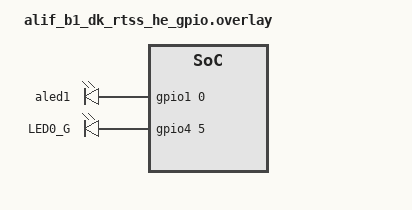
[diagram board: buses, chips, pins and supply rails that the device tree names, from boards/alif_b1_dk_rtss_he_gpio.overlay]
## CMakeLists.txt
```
# Copyright Alif Semiconductor - All Rights Reserved.
# Use, distribution and modification of this code is permitted under the
# terms stated in the Alif Semiconductor Software License Agreement
#
# You should have received a copy of the Alif Semiconductor Software
# License Agreement with this file. If not, please write to:
# contact@alifsemi.com, or visit: https://alifsemi.com/license

cmake_minimum_required(VERSION 3.20.0)
find_package(Zephyr REQUIRED HINTS $ENV{ZEPHYR_BASE})
project(alif_gpio)

target_sources(app PRIVATE
    src/main.c
    src/test_gpio.c
    src/test_gpio_interrupts.c
    src/test_gpio_stress.c
    )
```

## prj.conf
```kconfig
# Copyright Alif Semiconductor - All Rights Reserved.
# Use, distribution and modification of this code is permitted under the
# terms stated in the Alif Semiconductor Software License Agreement
#
# You should have received a copy of the Alif Semiconductor Software
# License Agreement with this file. If not, please write to:
# contact@alifsemi.com, or visit: https://alifsemi.com/license

CONFIG_GPIO=y
CONFIG_ZTEST=y
CONFIG_GPIO_GET_DIRECTION=y
CONFIG_GPIO_ENABLE_DISABLE_INTERRUPT=y
```

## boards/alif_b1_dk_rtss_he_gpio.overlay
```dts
/* Copyright (C) 2025 Alif Semiconductor - All Rights Reserved.
 * Use, distribution and modification of this code is permitted under the
 * terms stated in the Alif Semiconductor Software License Agreement
 *
 * You should have received a copy of the Alif Semiconductor Software
 * License Agreement with this file. If not, please write to:
 * contact@alifsemi.com, or visit: https://alifsemi.com/license
 */

/{
	aliases {
		led1 = &aled1;
		led0 = &aled0;
	};

	leds {
		aled1: led_1 {
			gpios = <&gpio1 0 0>;
		};
		aled0: led_0 {
			gpios = <&gpio4 5 0>;
			label = "LED0_G";
		};
	};
};

&gpio1 {
	status = "okay";
};

&gpio4 {
	status = "okay";
};
```

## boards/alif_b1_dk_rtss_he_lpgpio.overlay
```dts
/* Copyright (C) 2025 Alif Semiconductor - All Rights Reserved.
 * Use, distribution and modification of this code is permitted under the
 * terms stated in the Alif Semiconductor Software License Agreement
 *
 * You should have received a copy of the Alif Semiconductor Software
 * License Agreement with this file. If not, please write to:
 * contact@alifsemi.com, or visit: https://alifsemi.com/license
 */

/{
	aliases {
		led1 = &aled1;
		led0 = &aled0;
	};

	leds {
		aled1: led_1 {
			gpios = <&lpgpio 0 0>;
		};
		aled0: led_0 {
			gpios = <&gpio6 2 0>;
		};
	};
};

&lpgpio {
	status = "okay";
};

&gpio6 {
	status = "okay";
};
```

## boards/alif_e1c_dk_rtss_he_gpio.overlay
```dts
/* Copyright (C) 2025 Alif Semiconductor - All Rights Reserved.
 * Use, distribution and modification of this code is permitted under the
 * terms stated in the Alif Semiconductor Software License Agreement
 *
 * You should have received a copy of the Alif Semiconductor Software
 * License Agreement with this file. If not, please write to:
 * contact@alifsemi.com, or visit: https://alifsemi.com/license
 */

/{
	aliases {
		led1 = &aled1;
		led0 = &aled0;
	};

	leds {
		aled1: led_1 {
			gpios = <&gpio1 0 0>;
		};
		aled0: led_0 {
			gpios = <&gpio4 5 0>;
			label = "LED0_G";
		};
	};
};
```

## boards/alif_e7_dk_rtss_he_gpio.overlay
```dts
/* Copyright (C) 2025 Alif Semiconductor - All Rights Reserved.
 * Use, distribution and modification of this code is permitted under the
 * terms stated in the Alif Semiconductor Software License Agreement
 *
 * You should have received a copy of the Alif Semiconductor Software
 * License Agreement with this file. If not, please write to:
 * contact@alifsemi.com, or visit: https://alifsemi.com/license
 */

/{
	aliases {
		led1 = &aled1;
		led0 = &aled0;
	};

	leds {
		aled1: led_1 {
			gpios = <&gpio1 7 0>;
		};
		aled0: led_0 {
			gpios = <&gpio6 4 0>;
		};
	};
};

&gpio1 {
	status = "okay";
};
```

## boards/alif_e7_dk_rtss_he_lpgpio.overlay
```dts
/* Copyright (C) 2025 Alif Semiconductor - All Rights Reserved.
 * Use, distribution and modification of this code is permitted under the
 * terms stated in the Alif Semiconductor Software License Agreement
 *
 * You should have received a copy of the Alif Semiconductor Software
 * License Agreement with this file. If not, please write to:
 * contact@alifsemi.com, or visit: https://alifsemi.com/license
 */

/{
	aliases {
		led1 = &aled1;
		led0 = &aled0;
	};

	leds {
		aled1: led_1 {
			gpios = <&lpgpio 4 0>;
		};
		aled0: led_0 {
			gpios = <&gpio6 2 0>;
		};
	};
};

&lpgpio {
	status = "okay";
};
```

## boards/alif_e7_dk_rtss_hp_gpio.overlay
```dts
/* Copyright (C) 2025 Alif Semiconductor - All Rights Reserved.
 * Use, distribution and modification of this code is permitted under the
 * terms stated in the Alif Semiconductor Software License Agreement
 *
 * You should have received a copy of the Alif Semiconductor Software
 * License Agreement with this file. If not, please write to:
 * contact@alifsemi.com, or visit: https://alifsemi.com/license
 */

/{
	aliases {
		led1 = &aled1;
		led0 = &aled0;
	};

	leds {
		aled1: led_1 {
			gpios = <&gpio1 7 0>;
		};
		aled0: led_0 {
			gpios = <&gpio6 2 0>;
		};
	};
};

&gpio1 {
	status = "okay";
};

&gpio6 {
	status = "okay";
};
```

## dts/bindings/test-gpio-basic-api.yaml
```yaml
description: GPIO basic API test node

compatible: "test-gpio-basic-api"

properties:
  out-gpios:
    type: phandle-array
    required: true
  in-gpios:
    type: phandle-array
    required: true
```

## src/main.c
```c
/* Copyright Alif Semiconductor - All Rights Reserved.
 * Use, distribution and modification of this code is permitted under the
 * terms stated in the Alif Semiconductor Software License Agreement
 *
 * You should have received a copy of the Alif Semiconductor Software
 * License Agreement with this file. If not, please write to:
 * contact@alifsemi.com, or visit: https://alifsemi.com/license
 */

#include "test_gpio.h"

/*
 * Test suites exposed by this test application. Each suite holds only
 * Alif-unique coverage that is not already provided by Zephyr's upstream
 * tests/drivers/gpio/gpio_basic_api conformance test:
 *   - gpio_check            : direction-query API (gpio_pin_is_input_dt /
 *                             gpio_pin_is_output_dt) across pin lifecycle
 *                             plus Alif-specific corner cases.
 *   - gpio_test_interrupts  : multi-input single-output interrupt topology.
 *   - gpio_stress           : high-iteration stress and per-call
 *                             performance micro-benchmarks for the
 *                             GPIO data-path APIs, plus an edge-storm
 *                             regression for the interrupt path.
 */
ZTEST_SUITE(gpio_check, NULL, NULL, NULL, NULL, NULL);
ZTEST_SUITE(gpio_test_interrupts, NULL, NULL, NULL, NULL, NULL);
ZTEST_SUITE(gpio_stress, NULL, NULL, NULL, NULL, NULL);
```

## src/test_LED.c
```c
/* Copyright Alif Semiconductor - All Rights Reserved.
 * Use, distribution and modification of this code is permitted under the
 * terms stated in the Alif Semiconductor Software License Agreement
 *
 * You should have received a copy of the Alif Semiconductor Software
 * License Agreement with this file. If not, please write to:
 * contact@alifsemi.com, or visit: https://alifsemi.com/license
 */

#include "test_gpio.h"

static const struct gpio_dt_spec led = GPIO_DT_SPEC_GET(LED0_NODE, gpios);

/*
 * \brief  Function: GPIO_Configure
 *
 * \details Configure a single pin from a gpio_dt_spec and some extra flags.
 *          This is equivalent to:
 *          gpio_pin_configure(spec->port, spec->pin, spec->dt_flags | extra_flags);
 */
static int GPIO_Configure(void)
{
	int ret;

	ret = gpio_pin_configure_dt(&led, GPIO_OUTPUT_ACTIVE);
	zassert_equal(ret, 0, "Failed to configure interrupt");
	zassert_not_equal(ret, -EIO, "Operation is not implemented"
			" by the driver.\n");
	zassert_not_equal(ret, EWOULDBLOCK, "Operation would block.\n");

	return TC_PASS;
}

/*
 * \brief  Function: LED_toggle
 *
 * \details Toggle pin level from a gpio_dt_spec.
 *          This is equivalent to:
 *          gpio_pin_toggle(spec->port, spec->pin);
 */
static int LED_toggle(void)
{
	int ret;
	int i = 0;

	GPIO_Configure();

	while (i < 5) {
		ret = gpio_pin_toggle_dt(&led);
		zassert_equal(ret, 0, "Failed to configure interrupt");
		zassert_not_equal(ret, -EIO, "Operation is not implemented"
				" by the driver.\n");
		zassert_not_equal(ret, EWOULDBLOCK, "Operation would block.\n");

		k_msleep(SLEEP_TIME_MS);
		i++;
	}

	return TC_PASS;
}

/*
 * Test Case to test GPIO Configure
 *
 */
ZTEST(gpio_LED, test_b_GPIO_Configure)
{
	zassert_equal(GPIO_Configure(), TC_PASS, NULL);
}

/*
 * Test Case to test GPIO DE-BOUNCE
 *
 */
ZTEST(gpio_LED, test_d_gpio_toggle)
{
	zassert_equal(LED_toggle(), TC_PASS, NULL);
}
```

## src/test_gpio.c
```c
/* Copyright Alif Semiconductor - All Rights Reserved.
 * Use, distribution and modification of this code is permitted under the
 * terms stated in the Alif Semiconductor Software License Agreement
 *
 * You should have received a copy of the Alif Semiconductor Software
 * License Agreement with this file. If not, please write to:
 * contact@alifsemi.com, or visit: https://alifsemi.com/license
 */

/*
 * Alif-unique GPIO coverage.
 *
 * Zephyr's upstream gpio_basic_api conformance test
 * (tests/drivers/gpio/gpio_basic_api) already exercises pin
 * configuration, raw/logical read and write, bitwise port
 * operations, toggle, pull-up/pull-down and callback management.
 * Those behaviours are therefore NOT re-tested here.
 *
 * What is covered in this file is the direction-query API
 * (gpio_pin_is_input_dt() and gpio_pin_is_output_dt()), which the
 * upstream suite does not exercise. A single consolidated test
 * walks the pin through the three relevant states (un-configured,
 * input and output) and verifies the query API reports the expected
 * direction after each transition.
 */

#include "test_gpio.h"

extern int check_pin_conf(int ret);

static int check_pin_is_input(int ret)
{
	if (ret == -ENOSYS) {
		TC_PRINT("gpio_pin_is_input_dt not implemented by driver\n");
		ztest_test_skip();
		return -1;
	}
	if (ret < 0) {
		TC_PRINT("Unexpected error from gpio_pin_is_input_dt: %d\n", ret);
		return -1;
	}
	return (ret == 1) ? 0 : -1;
}

static int check_pin_is_output(int ret)
{
	if (ret == -ENOSYS) {
		TC_PRINT("gpio_pin_is_output_dt not implemented by driver\n");
		ztest_test_skip();
		return -1;
	}
	if (ret < 0) {
		TC_PRINT("Unexpected error from gpio_pin_is_output_dt: %d\n", ret);
		return -1;
	}
	return (ret == 1) ? 0 : -1;
}

/*
 * Number of INPUT<->OUTPUT reconfigure cycles performed by the
 * reconfiguration corner-case test. Chosen high enough to catch
 * state-leak bugs but low enough to keep total runtime under a
 * second even on slow simulators.
 */
#define RECONFIGURE_CYCLES 50

/*
 * Pin index that must exceed any reasonable ngpios value on the
 * controller backing GPIO_NODE. The DesignWare IP on Alif Ensemble
 * Gen2 instances supports at most 8 pins per port, so pin 31 is
 * always out of range and must be rejected with -EINVAL.
 */
#define OUT_OF_RANGE_PIN 31

/*
 * Verify gpio_pin_is_input_dt() / gpio_pin_is_output_dt() report
 * the correct direction across the pin's lifecycle:
 *   1) Before any configuration the pin is neither input nor output.
 *   2) After GPIO_INPUT it is input and not output.
 *   3) After GPIO_OUTPUT_LOW it is output and not input.
 * This coverage is NOT provided by the upstream gpio_basic_api test.
 */
ZTEST(gpio_check, test_gpio_direction_query)
{
	static const struct gpio_dt_spec gpio_port = GPIO_DT_SPEC_GET(GPIO_NODE, gpios);
	int rv;

	zassert_true(gpio_is_ready_dt(&gpio_port), "GPIO dev is not ready");

	/* 1. Pre-configuration: pin is neither input nor output. */
	rv = gpio_pin_is_input_dt(&gpio_port);
	zassert_not_equal(check_pin_is_input(rv), 0,
			  "Unconfigured pin reported as input");

	rv = gpio_pin_is_output_dt(&gpio_port);
	zassert_not_equal(check_pin_is_output(rv), 0,
			  "Unconfigured pin reported as output");

	/* 2. Configure as input: queries must reflect input. */
	zassert_equal(check_pin_conf(gpio_pin_configure_dt(&gpio_port, GPIO_INPUT)), 0,
		      "Failed to configure input pin");

	rv = gpio_pin_is_input_dt(&gpio_port);
	zassert_equal(check_pin_is_input(rv), 0,
		      "Pin is not reported as input after GPIO_INPUT");

	rv = gpio_pin_is_output_dt(&gpio_port);
	zassert_not_equal(check_pin_is_output(rv), 0,
			  "Input pin incorrectly reported as output");

	/* 3. Configure as output: queries must reflect output. */
	zassert_equal(check_pin_conf(gpio_pin_configure_dt(&gpio_port, GPIO_OUTPUT_LOW)), 0,
		      "Failed to configure output pin");

	rv = gpio_pin_is_output_dt(&gpio_port);
	zassert_equal(check_pin_is_output(rv), 0,
		      "Pin is not reported as output after GPIO_OUTPUT_LOW");

	rv = gpio_pin_is_input_dt(&gpio_port);
	zassert_not_equal(check_pin_is_input(rv), 0,
			  "Output pin incorrectly reported as input");
}

/*
 * Corner case: configuring a pin as input AND output simultaneously
 * is not supported by the DesignWare GPIO IP (it has no separate
 * drive/receive enables), so the driver must reject the request with
 * -ENOTSUP. Not covered by upstream gpio_basic_api.
 */
ZTEST(gpio_check, test_gpio_invalid_simultaneous_in_out)
{
	static const struct gpio_dt_spec gpio_port = GPIO_DT_SPEC_GET(GPIO_NODE, gpios);
	int rc;

	zassert_true(gpio_is_ready_dt(&gpio_port), "GPIO dev is not ready");

	rc = gpio_pin_configure_dt(&gpio_port, GPIO_INPUT | GPIO_OUTPUT);
	zassert_equal(rc, -ENOTSUP,
		      "Simultaneous GPIO_INPUT|GPIO_OUTPUT should be rejected "
		      "with -ENOTSUP, got %d", rc);

	rc = gpio_pin_configure_dt(&gpio_port, GPIO_DISCONNECTED);
	zassert_true(rc == 0 || rc == -ENOTSUP,
		     "GPIO_DISCONNECTED should be accepted or reported "
		     "-ENOTSUP, got %d", rc);
}

/*
 * Corner case: addressing a pin index outside the controller's
 * ngpios range must fail with -EINVAL, without side-effects on valid
 * pins. Not covered by upstream gpio_basic_api.
 */
ZTEST(gpio_check, test_gpio_invalid_pin_index)
{
	/*
	 * Zephyr's gpio_pin_configure() contains an __ASSERT that validates
	 * the pin against port_pin_mask before the driver is called.  When
	 * CONFIG_ASSERT is enabled this fires a kernel panic for out-of-range
	 * pins, so skip in that configuration.
	 */
	Z_TEST_SKIP_IFDEF(CONFIG_ASSERT);

	static const struct gpio_dt_spec gpio_port = GPIO_DT_SPEC_GET(GPIO_NODE, gpios);
	int rc;

	zassert_true(gpio_is_ready_dt(&gpio_port), "GPIO dev is not ready");

	rc = gpio_pin_configure(gpio_port.port, OUT_OF_RANGE_PIN, GPIO_INPUT);
	zassert_equal(rc, -EINVAL,
		      "Configuring out-of-range pin %d should fail with "
		      "-EINVAL, got %d", OUT_OF_RANGE_PIN, rc);

	/* Valid pin must still be configurable afterwards. */
	rc = gpio_pin_configure_dt(&gpio_port, GPIO_INPUT);
	zassert_equal(check_pin_conf(rc), 0,
		      "Valid pin reconfiguration after invalid-pin attempt failed");
}

/*
 * Stress corner case: flip the pin direction between INPUT and
 * OUTPUT many times in a row. This exposes state-leak bugs in the
 * direction or data registers and verifies the direction-query API
 * stays consistent on every transition. Not covered by upstream.
 */
ZTEST(gpio_check, test_gpio_reconfigure_cycles)
{
	static const struct gpio_dt_spec gpio_port = GPIO_DT_SPEC_GET(GPIO_NODE, gpios);
	int rc;
	int rv;

	zassert_true(gpio_is_ready_dt(&gpio_port), "GPIO dev is not ready");

	for (unsigned int i = 0; i < RECONFIGURE_CYCLES; i++) {
		rc = gpio_pin_configure_dt(&gpio_port, GPIO_INPUT);
		zassert_equal(check_pin_conf(rc), 0,
			      "Iter %u: configure INPUT failed", i);

		rv = gpio_pin_is_input_dt(&gpio_port);
		zassert_equal(check_pin_is_input(rv), 0,
			      "Iter %u: pin not reported as input", i);

		rc = gpio_pin_configure_dt(&gpio_port, GPIO_OUTPUT_LOW);
		zassert_equal(check_pin_conf(rc), 0,
			      "Iter %u: configure OUTPUT failed", i);

		rv = gpio_pin_is_output_dt(&gpio_port);
		zassert_equal(check_pin_is_output(rv), 0,
			      "Iter %u: pin not reported as output", i);
	}

	TC_PRINT("Completed %u INPUT<->OUTPUT reconfigure cycles with stable "
		 "direction-query results\n", RECONFIGURE_CYCLES);
}
```

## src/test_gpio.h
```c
/* Copyright Alif Semiconductor - All Rights Reserved.
 * Use, distribution and modification of this code is permitted under the
 * terms stated in the Alif Semiconductor Software License Agreement
 *
 * You should have received a copy of the Alif Semiconductor Software
 * License Agreement with this file. If not, please write to:
 * contact@alifsemi.com, or visit: https://alifsemi.com/license
 */

#ifndef ALIF_GPIO_TEST_GPIO_H_
#define ALIF_GPIO_TEST_GPIO_H_

#include <errno.h>
#include <zephyr/kernel.h>
#include <zephyr/drivers/gpio.h>
#include <zephyr/ztest.h>

/*
 * Devicetree aliases used by the Alif-specific GPIO tests.
 *   led0  - primary output (driven high/low to stimulate inputs).
 *   led1  - primary input under test (GPIO_NODE).
 *   led2  - optional second input for the multi-input interrupt test.
 */
#define GPIO_NODE   DT_ALIAS(led1)

#endif /* ALIF_GPIO_TEST_GPIO_H_ */
```

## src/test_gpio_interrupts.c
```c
/* Copyright Alif Semiconductor - All Rights Reserved.
 * Use, distribution and modification of this code is permitted under the
 * terms stated in the Alif Semiconductor Software License Agreement
 *
 * You should have received a copy of the Alif Semiconductor Software
 * License Agreement with this file. If not, please write to:
 * contact@alifsemi.com, or visit: https://alifsemi.com/license
 */

/*
 * Alif-unique GPIO interrupt coverage.
 *
 * Edge, level, add/remove, enable/disable and self-remove callback
 * flows are already covered by Zephyr's upstream
 * tests/drivers/gpio/gpio_basic_api conformance test
 * (gpio_port_cb_vari and gpio_port_cb_mgmt suites) and are therefore
 * NOT duplicated here.
 *
 * The only scenario retained in this file is multi-input / single-
 * output: two independent input pins wired to the same output
 * source, each with its own gpio_callback registered on a different
 * controller/pin, exercised together. That wiring topology is not
 * expressible in the upstream single-IN/single-OUT test harness and
 * so remains valuable as Alif-specific coverage.
 */

#include "test_gpio.h"
#include <zephyr/drivers/gpio.h>

/* Shared helpers also used from test_gpio.c */
int check_pin_conf(int ret)
{
	if (ret == 0) {
		return 0;
	}
	if (ret == -ENOTSUP) {
		TC_PRINT("Pin configuration option not supported\n");
		ztest_test_skip();
	}
	return -1;
}

static int check_cb_res(int ret)
{
	return (ret == 0) ? 0 : -1;
}

static int check_int_conf(int ret)
{
	if (ret == 0) {
		return 0;
	}
	if (ret == -ENOTSUP) {
		TC_PRINT("Interrupt configuration not supported\n");
		ztest_test_skip();
	}
	return -1;
}

static int check_pin_toggle(int ret)
{
	return (ret == 0) ? 0 : -1;
}

#define LED0_NODE  DT_ALIAS(led0)

static const struct gpio_dt_spec led = GPIO_DT_SPEC_GET(LED0_NODE, gpios);

#if DT_HAS_ALIAS(led2)

static const struct gpio_dt_spec gpio_in1 = GPIO_DT_SPEC_GET(GPIO_NODE, gpios);
static const struct gpio_dt_spec gpio_in2 = GPIO_DT_SPEC_GET(DT_ALIAS(led2), gpios);

static volatile int cb_multi_in1_count;
static volatile int cb_multi_in2_count;

static void callback_multi_in1(const struct device *port, struct gpio_callback *cb,
			       gpio_port_pins_t pins)
{
	ARG_UNUSED(port);
	ARG_UNUSED(cb);

	if (pins & BIT(gpio_in1.pin)) {
		cb_multi_in1_count++;
	}
}

static void callback_multi_in2(const struct device *port, struct gpio_callback *cb,
			       gpio_port_pins_t pins)
{
	ARG_UNUSED(port);
	ARG_UNUSED(cb);

	if (pins & BIT(gpio_in2.pin)) {
		cb_multi_in2_count++;
	}
}

static void drive_led_edges(int count)
{
	for (int i = 0; i < count; i++) {
		zassert_equal(check_pin_toggle(gpio_pin_toggle_dt(&led)), 0,
			      "Failed to toggle LED pin");
		k_msleep(100);
	}
}

/*
 * Alif-unique: two inputs driven from a single output trigger
 * independent callbacks. Upstream gpio_basic_api only supports one
 * IN/OUT pair, so this wiring topology is not otherwise exercised.
 */
ZTEST(gpio_test_interrupts, test_gpio_multi_input_single_output_interrupt)
{
	struct gpio_callback gpio_cb_in1;
	struct gpio_callback gpio_cb_in2;
	int in1_initial;
	int in2_initial;
	bool in1_toggled = false;
	bool in2_toggled = false;
	int ret;

	zassert_true(gpio_is_ready_dt(&gpio_in1), "GPIO input1 dev is not ready");
	zassert_true(gpio_is_ready_dt(&gpio_in2), "GPIO input2 dev is not ready");
	zassert_true(gpio_is_ready_dt(&led), "GPIO output dev is not ready");

	zassert_equal(check_int_conf(gpio_pin_interrupt_configure_dt(&gpio_in1,
								     GPIO_INT_DISABLE)),
		      0, "Disable input1 interrupt failed");
	zassert_equal(check_int_conf(gpio_pin_interrupt_configure_dt(&gpio_in2,
								     GPIO_INT_DISABLE)),
		      0, "Disable input2 interrupt failed");

	zassert_equal(check_pin_conf(gpio_pin_configure_dt(&gpio_in1, GPIO_INPUT)), 0,
		      "Configure input1 pin failed");
	zassert_equal(check_pin_conf(gpio_pin_configure_dt(&gpio_in2, GPIO_INPUT)), 0,
		      "Configure input2 pin failed");
	zassert_equal(check_pin_conf(gpio_pin_configure_dt(&led, GPIO_OUTPUT_ACTIVE)), 0,
		      "Configure output pin failed");

	gpio_init_callback(&gpio_cb_in1, callback_multi_in1, BIT(gpio_in1.pin));
	zassert_equal(check_cb_res(gpio_add_callback(gpio_in1.port, &gpio_cb_in1)), 0,
		      "Add callback for input1 failed");

	gpio_init_callback(&gpio_cb_in2, callback_multi_in2, BIT(gpio_in2.pin));
	zassert_equal(check_cb_res(gpio_add_callback(gpio_in2.port, &gpio_cb_in2)), 0,
		      "Add callback for input2 failed");

	ret = gpio_pin_interrupt_configure_dt(&gpio_in1, GPIO_INT_EDGE_BOTH);
	zassert_equal(check_int_conf(ret), 0, "Enable input1 interrupt failed");

	ret = gpio_pin_interrupt_configure_dt(&gpio_in2, GPIO_INT_EDGE_BOTH);
	zassert_equal(check_int_conf(ret), 0, "Enable input2 interrupt failed");

	in1_initial = gpio_pin_get_dt(&gpio_in1);
	in2_initial = gpio_pin_get_dt(&gpio_in2);

	cb_multi_in1_count = 0;
	cb_multi_in2_count = 0;
	for (int i = 0; i < 10; i++) {
		drive_led_edges(1);
		if (gpio_pin_get_dt(&gpio_in1) != in1_initial) {
			in1_toggled = true;
		}
		if (gpio_pin_get_dt(&gpio_in2) != in2_initial) {
			in2_toggled = true;
		}
	}

	if (!in2_toggled) {
		TC_PRINT("Input2 (led2) did not toggle; check wiring led0->led2.\n");
		/* Cleanup before skip */
		gpio_pin_interrupt_configure_dt(&gpio_in1, GPIO_INT_DISABLE);
		gpio_pin_interrupt_configure_dt(&gpio_in2, GPIO_INT_DISABLE);
		gpio_remove_callback(gpio_in1.port, &gpio_cb_in1);
		gpio_remove_callback(gpio_in2.port, &gpio_cb_in2);
		gpio_pin_configure_dt(&led, GPIO_INPUT);
		ztest_test_skip();
	}

	zassert_true(in1_toggled, "Input1 did not toggle; check wiring");
	zassert_true(cb_multi_in1_count > 0, "No interrupt seen on input1");
	zassert_true(cb_multi_in2_count > 0, "No interrupt seen on input2");

	zassert_equal(check_int_conf(gpio_pin_interrupt_configure_dt(&gpio_in1,
								     GPIO_INT_DISABLE)),
		      0, "Disable input1 interrupt failed");
	zassert_equal(check_int_conf(gpio_pin_interrupt_configure_dt(&gpio_in2,
								     GPIO_INT_DISABLE)),
		      0, "Disable input2 interrupt failed");

	zassert_equal(check_cb_res(gpio_remove_callback(gpio_in1.port, &gpio_cb_in1)), 0,
		      "Remove callback for input1 failed");
	zassert_equal(check_cb_res(gpio_remove_callback(gpio_in2.port, &gpio_cb_in2)), 0,
		      "Remove callback for input2 failed");

	/* Restore led0 to input/Hi-Z to avoid conflicts with later tests */
	zassert_equal(check_pin_conf(gpio_pin_configure_dt(&led, GPIO_INPUT)), 0,
		      "Restore output pin to input failed");
}

#else /* !DT_HAS_ALIAS(led2) */

ZTEST(gpio_test_interrupts, test_gpio_multi_input_single_output_interrupt)
{
	TC_PRINT("led2 alias not present in devicetree; skipping multi-input test.\n");
	ztest_test_skip();
}

#endif /* DT_HAS_ALIAS(led2) */
```

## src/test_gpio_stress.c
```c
/* Copyright Alif Semiconductor - All Rights Reserved.
 * Use, distribution and modification of this code is permitted under the
 * terms stated in the Alif Semiconductor Software License Agreement
 *
 * You should have received a copy of the Alif Semiconductor Software
 * License Agreement with this file. If not, please write to:
 * contact@alifsemi.com, or visit: https://alifsemi.com/license
 */

/*
 * Alif GPIO stress and performance coverage.
 *
 * This file adds tests that the upstream Zephyr gpio_basic_api
 * conformance suite does NOT provide:
 *   - High iteration-count stress over the data-path APIs
 *     (set / clear / toggle / get) to catch regressions that only
 *     surface under sustained load.
 *   - Micro-benchmarks that measure and report the average number
 *     of CPU cycles per gpio_pin_{set,get,toggle}_dt() call.
 *     Results are printed only; no hard thresholds are asserted
 *     because absolute timing depends on bus wait-states and
 *     compiler optimisation level. The tests still fail if any
 *     underlying API call returns an error.
 *   - Interrupt storm: many fast edges on a cross-wired input pin
 *     with an EDGE_BOTH callback registered, verifying that the
 *     driver delivers at least a minimum expected number of
 *     callbacks without losing or crashing.
 *
 * Wiring assumptions mirror the multi-input interrupt test:
 *   led0  -> output used to drive the cross-wired input.
 *   led1  -> primary pin under test (GPIO_NODE, also used as
 *            stand-alone output for stress/perf when no physical
 *            jumper to led0 is present).
 */

#include "test_gpio.h"

#define TOGGLE_STRESS_ITERATIONS 10000
#define PERF_ITERATIONS          2000
#define INT_STORM_EDGES          200
#define INT_STORM_MIN_CALLBACKS  1
#define INT_STORM_EDGE_DELAY_US  500

#define LED0_NODE DT_ALIAS(led0)

static const struct gpio_dt_spec stress_pin = GPIO_DT_SPEC_GET(GPIO_NODE, gpios);

static uint32_t avg_cycles(uint32_t total_cycles, uint32_t iterations)
{
	return iterations ? (total_cycles / iterations) : 0U;
}

/*
 * Run TOGGLE_STRESS_ITERATIONS back-to-back toggles on a single
 * output pin and assert every call returned success. This catches
 * drive-path regressions that only manifest under sustained load,
 * which the upstream suite (small fixed-count toggles) does not.
 */
ZTEST(gpio_stress, test_gpio_toggle_stress)
{
	int rc;
	uint32_t start;
	uint32_t duration_us;

	zassert_true(gpio_is_ready_dt(&stress_pin), "GPIO dev is not ready");

	rc = gpio_pin_configure_dt(&stress_pin, GPIO_OUTPUT_LOW);
	zassert_equal(rc, 0, "Failed to configure output pin");

	start = k_cycle_get_32();
	for (unsigned int i = 0; i < TOGGLE_STRESS_ITERATIONS; i++) {
		rc = gpio_pin_toggle_dt(&stress_pin);
		zassert_equal(rc, 0, "Toggle failed at iter %u: %d", i, rc);
	}
	duration_us = k_cyc_to_us_floor32(k_cycle_get_32() - start);

	TC_PRINT("Toggle stress: %u iterations completed in %u us (%u us avg)\n",
		 TOGGLE_STRESS_ITERATIONS, duration_us,
		 TOGGLE_STRESS_ITERATIONS ? (duration_us / TOGGLE_STRESS_ITERATIONS)
					  : 0U);
}

/*
 * Measure and report average cycles per gpio_pin_set_dt() call,
 * alternating between 1 and 0 so the driver cannot short-circuit
 * identical writes.
 */
ZTEST(gpio_stress, test_gpio_pin_set_performance)
{
	int rc;
	uint32_t start;
	uint32_t total;

	zassert_true(gpio_is_ready_dt(&stress_pin), "GPIO dev is not ready");

	rc = gpio_pin_configure_dt(&stress_pin, GPIO_OUTPUT_LOW);
	zassert_equal(rc, 0, "Failed to configure output pin");

	start = k_cycle_get_32();
	for (unsigned int i = 0; i < PERF_ITERATIONS; i++) {
		rc = gpio_pin_set_dt(&stress_pin, i & 1);
		zassert_equal(rc, 0, "pin_set failed at iter %u: %d", i, rc);
	}
	total = k_cycle_get_32() - start;

	TC_PRINT("gpio_pin_set_dt perf: %u iters, %u cycles total, "
		 "%u cycles/call (%u ns/call)\n",
		 PERF_ITERATIONS, total,
		 avg_cycles(total, PERF_ITERATIONS),
		 k_cyc_to_ns_floor32(avg_cycles(total, PERF_ITERATIONS)));
}

/*
 * Measure and report average cycles per gpio_pin_get_dt() call on
 * the same pin after driving it high. The read result is asserted
 * for consistency (all calls must read the same level) to prevent
 * the optimiser from eliminating the loop body.
 */
ZTEST(gpio_stress, test_gpio_pin_get_performance)
{
	int rc;
	int val;
	uint32_t start;
	uint32_t total;
	int first_val;

	zassert_true(gpio_is_ready_dt(&stress_pin), "GPIO dev is not ready");

	rc = gpio_pin_configure_dt(&stress_pin, GPIO_OUTPUT_HIGH);
	zassert_equal(rc, 0, "Failed to configure output pin");

	/*
	 * Reading back an output pin returns the driven level on
	 * DesignWare GPIO, so the value must be stable for the
	 * entire measurement window.
	 */
	first_val = gpio_pin_get_dt(&stress_pin);
	zassert_true(first_val >= 0,
		     "Initial gpio_pin_get_dt failed: %d", first_val);

	start = k_cycle_get_32();
	for (unsigned int i = 0; i < PERF_ITERATIONS; i++) {
		val = gpio_pin_get_dt(&stress_pin);
		zassert_equal(val, first_val,
			      "pin_get drift at iter %u: got %d, expected %d",
			      i, val, first_val);
	}
	total = k_cycle_get_32() - start;

	TC_PRINT("gpio_pin_get_dt perf: %u iters, %u cycles total, "
		 "%u cycles/call (%u ns/call)\n",
		 PERF_ITERATIONS, total,
		 avg_cycles(total, PERF_ITERATIONS),
		 k_cyc_to_ns_floor32(avg_cycles(total, PERF_ITERATIONS)));
}

/*
 * Measure and report average cycles per gpio_pin_toggle_dt() call.
 */
ZTEST(gpio_stress, test_gpio_pin_toggle_performance)
{
	int rc;
	uint32_t start;
	uint32_t total;

	zassert_true(gpio_is_ready_dt(&stress_pin), "GPIO dev is not ready");

	rc = gpio_pin_configure_dt(&stress_pin, GPIO_OUTPUT_LOW);
	zassert_equal(rc, 0, "Failed to configure output pin");

	start = k_cycle_get_32();
	for (unsigned int i = 0; i < PERF_ITERATIONS; i++) {
		rc = gpio_pin_toggle_dt(&stress_pin);
		zassert_equal(rc, 0, "toggle failed at iter %u: %d", i, rc);
	}
	total = k_cycle_get_32() - start;

	TC_PRINT("gpio_pin_toggle_dt perf: %u iters, %u cycles total, "
		 "%u cycles/call (%u ns/call)\n",
		 PERF_ITERATIONS, total,
		 avg_cycles(total, PERF_ITERATIONS),
		 k_cyc_to_ns_floor32(avg_cycles(total, PERF_ITERATIONS)));
}

#if DT_HAS_ALIAS(led0)

static const struct gpio_dt_spec storm_out = GPIO_DT_SPEC_GET(LED0_NODE, gpios);
static const struct gpio_dt_spec storm_in  = GPIO_DT_SPEC_GET(GPIO_NODE, gpios);

static volatile unsigned int storm_cb_cnt;

static void storm_callback(const struct device *port, struct gpio_callback *cb,
			   gpio_port_pins_t pins)
{
	ARG_UNUSED(port);
	ARG_UNUSED(cb);

	if (pins & BIT(storm_in.pin)) {
		storm_cb_cnt++;
	}
}

/*
 * Interrupt storm: drive INT_STORM_EDGES edges on the output pin
 * with a short delay and verify that the edge-both callback ran
 * often enough. We only assert a low minimum because debounce or
 * sync paths may legitimately drop a fraction of very fast edges;
 * the intent is to ensure the driver does not hang or permanently
 * mis-mask interrupts under heavy edge traffic. The observed count
 * is printed for diagnostic purposes.
 */
ZTEST(gpio_stress, test_gpio_interrupt_storm)
{
	struct gpio_callback cb;
	int rc;
	unsigned int observed;

	if (!gpio_is_ready_dt(&storm_out) || !gpio_is_ready_dt(&storm_in)) {
		ztest_test_skip();
		return;
	}

	rc = gpio_pin_interrupt_configure_dt(&storm_in, GPIO_INT_DISABLE);
	zassert_equal(rc, 0, "Disable interrupt failed: %d", rc);

	rc = gpio_pin_configure_dt(&storm_in, GPIO_INPUT);
	zassert_equal(rc, 0, "Configure input failed: %d", rc);

	rc = gpio_pin_configure_dt(&storm_out, GPIO_OUTPUT_LOW);
	zassert_equal(rc, 0, "Configure output failed: %d", rc);

	gpio_init_callback(&cb, storm_callback, BIT(storm_in.pin));
	rc = gpio_add_callback(storm_in.port, &cb);
	zassert_equal(rc, 0, "Add callback failed: %d", rc);

	rc = gpio_pin_interrupt_configure_dt(&storm_in, GPIO_INT_EDGE_BOTH);
	if (rc == -ENOTSUP) {
		TC_PRINT("GPIO_INT_EDGE_BOTH not supported; skipping storm\n");
		gpio_remove_callback(storm_in.port, &cb);
		ztest_test_skip();
		return;
	}
	zassert_equal(rc, 0, "Enable EDGE_BOTH failed: %d", rc);

	storm_cb_cnt = 0;
	for (unsigned int i = 0; i < INT_STORM_EDGES; i++) {
		rc = gpio_pin_toggle_dt(&storm_out);
		zassert_equal(rc, 0, "toggle failed at edge %u: %d", i, rc);
		k_busy_wait(INT_STORM_EDGE_DELAY_US);
	}

	/* Allow any in-flight interrupts to drain. */
	k_msleep(50);
	observed = storm_cb_cnt;

	rc = gpio_pin_interrupt_configure_dt(&storm_in, GPIO_INT_DISABLE);
	zassert_equal(rc, 0, "Disable interrupt failed: %d", rc);

	rc = gpio_remove_callback(storm_in.port, &cb);
	zassert_equal(rc, 0, "Remove callback failed: %d", rc);

	TC_PRINT("Interrupt storm: drove %u edges, observed %u callbacks\n",
		 INT_STORM_EDGES, observed);

	zassert_not_equal(observed, 0U,
			  "No callbacks observed; possible broken interrupt path or missing led0->led1 jumper");
	zassert_true(observed >= INT_STORM_MIN_CALLBACKS,
		     "Edge storm produced only %u callbacks (min %u)",
		     observed, INT_STORM_MIN_CALLBACKS);
}

#else /* !DT_HAS_ALIAS(led0) */

ZTEST(gpio_stress, test_gpio_interrupt_storm)
{
	TC_PRINT("led0 alias not present in devicetree; skipping storm.\n");
	ztest_test_skip();
}

#endif /* DT_HAS_ALIAS(led0) */
```
